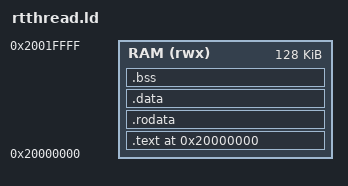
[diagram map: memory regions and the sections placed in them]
/* RT-Thread 链接脚本 */

OUTPUT_ARCH("riscv")
ENTRY(_start)

MEMORY
{
    RAM (rwx) : ORIGIN = 0x20000000, LENGTH = 128K
}

SECTIONS
{
    . = 0x20000000;

    .text : {
        *(.text.start)
        *(.text*)
    } > RAM

    .rodata : {
        *(.rodata*)
    } > RAM

    .data : {
        *(.data*)
    } > RAM

    .bss : {
        __bss_start = .;
        *(.bss*)
        *(COMMON)
        __bss_end = .;
    } > RAM

    . = ALIGN(8);
    __stack_top = ORIGIN(RAM) + LENGTH(RAM);
}
